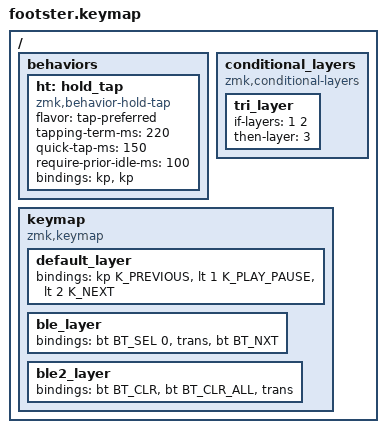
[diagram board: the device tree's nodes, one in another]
// Copyright (c) 2022 The ZMK Contributors
// SPDX-License-Identifier: MIT

#include <behaviors.dtsi>
#include <dt-bindings/zmk/keys.h>
#include <dt-bindings/zmk/bt.h>

// Home row mods macro
#define HRML(k1,k2,k3,k4) &ht LSHFT k1  &ht LALT k2  &ht LCTRL k3  &ht LGUI k4
#define HRMR(k1,k2,k3,k4) &ht RGUI k1  &ht RCTRL k2  &ht RALT k3  &ht RSHFT k4

/ {
    behaviors {
        ht: hold_tap {
            compatible = "zmk,behavior-hold-tap";
            #binding-cells = <2>;
            flavor = "tap-preferred";
            tapping-term-ms = <220>;
            quick-tap-ms = <150>;
            require-prior-idle-ms = <100>;
            bindings = <&kp>, <&kp>;
        };
    };

    conditional_layers {
        compatible = "zmk,conditional-layers";
        tri_layer {
            if-layers = <1 2>;
            then-layer = <3>;
        };
    };

    keymap {
        compatible = "zmk,keymap";
        default_layer {
            bindings = <
            &kp K_PREVIOUS      &lt 1 K_PLAY_PAUSE     &lt 2 K_NEXT
            >;
        };
        ble_layer {
            bindings = <
            &bt BT_SEL 0     &trans      &bt BT_NXT
            >;
        };
        ble2_layer {
            bindings = <
            &bt BT_CLR      &bt BT_CLR_ALL   &trans
            >;
        };
    };
};
